# ET6801 register map
Vendor: ETMCU Inc.; File version: v0.0.1
CPU: CM7 r2p1, little endian, MPU, FPU, I-cache, D-cache, ITCM, DTCM, 4 interrupt priority bits
Registers are 32-bit, read-write, reset 0x0 unless marked. A register's access mark holds for its fields unless they carry their own. Offsets are from the block's base; [hi:lo] are bit positions; lines under a group give offsets from that group; {n}, {i} and the like mark numbered series.

## ETIMER — Provide an overview of the purpose and functionality of the peripheral: etim_cfg
Base 0x40024000
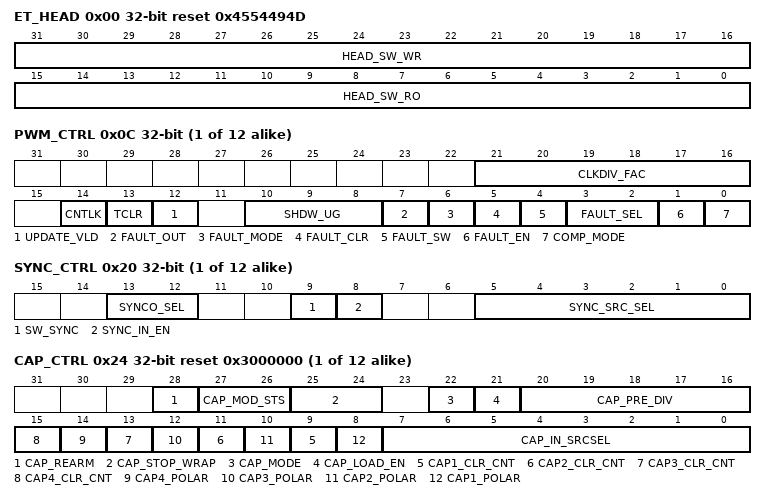
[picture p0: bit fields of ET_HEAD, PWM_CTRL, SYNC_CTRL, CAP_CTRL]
0x00 ET_HEAD reset 0x4554494D
  [31:16] HEAD_SW_WR — 软件测试读写寄存器，硬件无访问
  [15:0] HEAD_SW_RO ro — 软件只读上报寄存器，硬件无访问,ETIM的ASICII 码表示
{0x4+0x30*i} CORE[{i}] (i=0..11) group — CFG_ETIM_CORE
  0x00 COMPA
    [31:0] PWM_COMPA — eTimer COMPA比较值
  0x04 COMPB
    [31:0] PWM_COMPB — eTimer COMPB比较值
  0x08 EVENT_CNT
    [31:0] PWM_EVTCNT — eTimer输出配置值，计数到该寄存器配置值，有个对应的事件输出
  0x0C PWM_CTRL
    [21:16] CLKDIV_FAC — eTimer模块计数分频因子,计数值0~63； 实际分频数比配置值多1
    [14] CNTLK — 软件配置counter锁存，写1清，产生高脉冲
    [13] TCLR — 软件配置timer清零，写1清，产生高脉冲
    [12] UPDATE_VLD — eTimer COMPA/COMPB比较值更新标识，软件写1，硬件清零 该寄存器为1时，表示COMPA、COMPB已经刷新完成，硬件可以在shadow模式下更新配置值，避免shadow模式下只更新成功其中一个值； 与cfg_pwm_shdw_ug使用同一个寄存器，保证可以同时配置，使cfg_pwm_compa[31:0]， cfg_etm_pwm_compb[31:0]可以同时生效；
    [10:8] SHDW_UG — 影子加载模式使能，计数到周期值更新（相应bit为1使能对应影子加载模式；不使能默认为立即加载） bit0：周期值 ； bit1：COMPA+COMPB ； bit2：事件配置寄存器值；
    [7] FAULT_OUT — eTimer fault模式输出电平 0：输出低电平； 1：输出高电平；
    [6] FAULT_MODE — eTimer fault模式 0：CBC模式； 1：one-shot模式；
    [5] FAULT_CLR — eTimer one-shot fault模式清零信号，写1清，产生高脉冲
    [4] FAULT_SW — eTimer fault模式软件输入信号
    [3:2] FAULT_SEL — eTimer fault模式输入选择 0：软件输入； 1：XBAR0输入； 2：XBAR1输入； other：reserved。（硬件默认为软件输入）
    [1] FAULT_EN — eTimer是否进入fault模式 0：不进入fault模式； 1：进入fault模式；
    [0] COMP_MODE — eTimer比较模式 0：COMPA单一比较模式； 1：COMPA+COMPB模式；
  0x10 TIMER_CYC reset 0xFFFFFFFF
    [31:0] PWM_TCYC — 软件配置couter周期值
  0x14 LKCNT_RPT ro
    [31:0] PWM_LKCNT — cfg_etim_pwm_cntlk_r锁存后Counter上报值，只读
  0x18 RLCNT_RPT ro
    [31:0] PWM_RLCNT — Counter实时值上报，只读
  0x1C CTRPHS
    [31:0] SYNC_CTRPHS — 相位控制寄存器,同步信号到来时，加载此寄存器到计数器中
  0x20 SYNC_CTRL
    [13:12] SYNCO_SEL — 内部同步源etim_sync_out信号源选择： 'd0:选择软件配置同步 'd1:选择ETIM计数到周期同步 'd2:关闭etim_sync_out输出信号（输出为0） 'd3: 关闭etim_sync_out输出信号（输出为0）
    [9] SW_SYNC — 软件强制同步（写清） 'b0:无影响 'b1:写1产生软件强制同步
    [8] SYNC_IN_EN — Sync in模式选择 'b0:关闭sync_in进来的信号 'b1:使能sync_in进来的信号
    [5:0] SYNC_SRC_SEL — 同步输入源选择 选择SPWM、INPUTXBAR、ETIM的同步信号，如下所示： 'd0:SPWM0_SYNC 'd1:SPWM1_SYNC 'd2:SPWM2_SYNC 'd3:SPWM3_SYNC 'd4:SPWM4_SYNC 'd5:SPWM5_SYNC 'd6:SPWM6_SYNC 'd7:SPWM7_SYNC 'd8:SPWM8_SYNC 'd9:SPWM9_SYNC 'd10:SPWM10_SYNC 'd11: SPWM11_SYNC d12: SPWM12_SYNC 'd13: SPWM13_SYNC 'd14: SPWM14_SYNC 'd15: SPWM15_SYNC 'd16: SPWM16_SYNC 'd17: SPWM17_SYNC 'd18:INPUTXBAR0(XBAR CAP输入源低6位) 'd19: INPUTXBAR1(XBAR CAP输入源低6位) 'd20: INPUTXBAR2(XBAR CAP输入源低6位) 'd21: INPUTXBAR3(XBAR CAP输入源低6位) 'd22: INPUTXBAR4(XBAR CAP输入源低6位) 'd23: INPUTXBAR5(XBAR CAP输入源低6位) 'd24:ETIM0_SYNC_OUT 'd25:ETIM1_SYNC_OUT 'd26:ETIM2_SYNC_OUT 'd27:ETIM3_SYNC_OUT 'd28:ETIM4_SYNC_OUT 'd29:ETIM5_SYNC_OUT 'd30:ETIM6_SYNC_OUT 'd31:ETIM7_SYNC_OUT 'd32:ETIM8_SYNC_OUT 'd33:ETIM9_SYNC_OUT 'd34:ETIM10_SYNC_OUT 'd35:ETIM11_SYNC_OUT '36-63:1'b0'
  0x24 CAP_CTRL reset 0x3000000
    [28] CAP_REARM — 重新加载 'b0:无作用 'b1:针对one-shot模式 复位MOD4寄存器值到0，解冻MOD4计数器，使能CAP寄存器加载
    [27:26] CAP_MOD_STS ro — d0: CAP1寄存器在下一个捕获时刻加载 'd1: CAP2寄存器在下一个捕获时刻加载 'd2: CAP3寄存器在下一个捕获时刻加载 'd3: CAP4寄存器在下一个捕获时刻加载
    [25:24] CAP_STOP_WRAP — One-shot：停止计数值，停止时cap1~cap4寄存器将会被冻结 Continuous: 从该数开始重新进行计数 'd0:在捕获事件1发生后停止（one-shot）或者在捕获事件1后重新环绕 'd1:在捕获事件2发生后停止（one-shot）或者在捕获事件2后重新环绕 'd2:在捕获事件3发生后停止（one-shot）或者在捕获事件3后重新环绕 'd3:在捕获事件4发生后停止（one-shot）或者在捕获事件4后重新环绕
    [22] CAP_MODE — 捕获模式选择 'b0:continuous模式 'b1:one-shot模式
    [21] CAP_LOAD_EN — 加载CAP1~CAP4寄存器值 'b0:在捕获事件发生时，关闭加载CAP1~CAP4 'b1: 在捕获事件发生时，使能加载CAP1~CAP4
    [20:16] CAP_PRE_DIV — 配置CAP 预分频 'h0:by pass 'h1:预分频2 'h2:预分频4 'h3:预分频6 ...... 'h1e:预分频60 'h1f:预分频62
    [2n+7] CAP{n}_CLR_CNT (n=1..4) — 捕获事件{n}计数器清零 'b0:计数器不清零（绝对时间戳） 'b1:计数器清零（相对时间戳）
    [14] CAP4_POLAR — 捕获事件4极性选择 'b0:上升沿捕获事件4 'b1:下降沿捕获事件4
    [12] CAP3_POLAR — 捕获事件4极性选择 'b0:上升沿捕获事件3 'b1:下降沿捕获事件3
    [10] CAP2_POLAR — 捕获事件2极性选择 'b0:上升沿捕获事件2 'b1:下降沿捕获事件2
    [8] CAP1_POLAR — 捕获事件1极性选择 'b0:上升沿捕获事件1 'b1:下降沿捕获事件1
    [7:0] CAP_IN_SRCSEL — 8'd0 INPUTXBAR1 8'd1 INPUTXBAR2 8'd2 INPUTXBAR3 8'd3 INPUTXBAR4 8'd4 INPUTXBAR5 8'd5 INPUTXBAR6 8'd6 INPUTXBAR7 8'd7 INPUTXBAR8 8'd8 INPUTXBAR9 8'd9 INPUTXBAR10 8'd10 INPUTXBAR11 8'd11 INPUTXBAR12 8'd12 INPUTXBAR13 8'd13 INPUTXBAR14 8'd14 INPUTXBAR15 8'd15 INPUTXBAR16 8'd16 OUTPUTXBAR1 8'd17 OUTPUTXBAR2 8'd18 OUTPUTXBAR3 8'd19 OUTPUTXBAR4 8'd20 OUTPUTXBAR5 8'd21 OUTPUTXBAR6 8'd22 OUTPUTXBAR7 8'd23 OUTPUTXBAR8 8'd24 OUTPUTXBAR9 8'd25 OUTPUTXBAR10 8'd26 OUTPUTXBAR11 8'd27 OUTPUTXBAR12 8'd28 CLU1 8'd29 CLU2 8'd30 CLU3 8'd31 CLU4 8'd32 UART_rx0 8'd33 UART_rx1 8'd34 UART_rx2 8'd35 UART_rx3 8'd36 UART_rx4 8'd37 UART_rx5 8'd38 UART_rx6 8'd39 UART_rx7 8'd40 LIN0_RX 8'd41 LIN1_RX 8'd42 SPWM1 8'd43 SPWM2 8'd44 SPWM3 8'd45 SPWM4 8'd46 SPWM5 8'd47 SPWM6 8'd48 SPWM7 8'd49 SPWM8 8'd50 SPWM9 8'd51 SPWM10 8'd52 SPWM11 8'd53 SPWM12 8'd54 SPWM13 8'd55 SPWM14 8'd56 SPWM15 8'd57 SPWM16 8'd58 SPWM17 8'd59 SPWM18 8'd60 SPWM19 8'd61 SPWM20 8'd62 SPWM21 8'd63 SPWM22 8'd64 SPWM23 8'd65 SPWM24 8'd66 SPWM25 8'd67 SPWM26 8'd68 SPWM27 8'd69 SPWM28 8'd70 SPWM29 8'd71 SPWM30 8'd72 SPWM31 8'd73 SPWM32 8'd74 SPWM33 8'd75 SPWM34 8'd76 SPWM35 8'd77 SPWM36 8'd78 ETIM1_PWM 8'd79 ETIM2_PWM 8'd80 ETIM3_PWM 8'd81 ETIM4_PWM 8'd82 ETIM5_PWM 8'd83 ETIM6_PWM 8'd84 ETIM7_PWM 8'd85 ETIM8_PWM 8'd86 ETIM9_PWM 8'd87 ETIM10_PWM 8'd88 ETIM11_PWM 8'd89 ETIM12_PWM 8'd90 CMPSS1_CTRIPH 8'd91 CMPSS2_CTRIPH 8'd92 CMPSS3_CTRIPH 8'd93 CMPSS4_CTRIPH 8'd94 CMPSS5_CTRIPH 8'd95 CMPSS6_CTRIPH 8'd96 CMPSS7_CTRIPH 8'd97 CMPSS8_CTRIPH 8'd98 CMPSS9_CTRIPH 8'd99 CMPSS10_CTRIPH 8'd100 CMPSS11_CTRIPH 8'd101 CMPSS1_CTRIPL 8'd102 0 CMPSS2_CTRIPL 8'd103 1 CMPSS3_CTRIPL 8'd104 2 CMPSS4_CTRIPL 8'd105 3 CMPSS5_CTRIPL 8'd106 4 CMPSS6_CTRIPL 8'd107 5 CMPSS7_CTRIPL 8'd108 6 CMPSS8_CTRIPL 8'd109 7 CMPSS9_CTRIPL 8'd110 8 CMPSS10_CTRIPL 8'd111 9 CMPSS11_CTRIPL 8'd112 0 CMPSS1_CTRIPH OR CMPSS1_CTRIPL 8'd113 1 CMPSS2_CTRIPH OR CMPSS2_CTRIPL 8'd114 2 CMPSS3_CTRIPH OR CMPSS3_CTRIPL 8'd115 3 CMPSS4_CTRIPH OR CMPSS4_CTRIPL 8'd116 4 CMPSS5_CTRIPH OR CMPSS5_CTRIPL 8'd117 5 CMPSS6_CTRIPH OR CMPSS6_CTRIPL 8'd118 6 CMPSS7_CTRIPH OR CMPSS7_CTRIPL 8'd119 7 CMPSS8_CTRIPH OR CMPSS8_CTRIPL 8'd120 8 CMPSS9_CTRIPH OR CMPSS9_CTRIPL 8'd121 9 CMPSS10_CTRIPH OR CMPSS10_CTRIPL 8'd122 0 CMPSS11_CTRIPH OR CMPSS11_CTRIPL 8'd123 1 ADC1_CEVT1 8'd124 2 ADC1_CEVT2 8'd125 3 ADC1_CEVT3 8'd126 4 ADC1_CEVT4 8'd127 5 ADC2_CEVT1 8'd128 6 ADC2_CEVT2 8'd129 7 ADC2_CEVT3 8'd130 8 ADC2_CEVT4 8'd131 9 ADC3_CEVT1 8'd132 0 ADC3_CEVT2 8'd133 1 ADC3_CEVT3 8'd134 2 ADC3_CEVT4 8'd135 3 SDFM1FL1_CEVT1 8'd136 4 SDFM1FL2_CEVT1 8'd137 5 SDFM1FL3_CEVT1 8'd138 6 SDFM1FL4_CEVT1 8'd139 7 SDFM1FL1_CEVT2 8'd140 8 SDFM1FL2_CEVT2 8'd141 9 SDFM1FL3_CEVT2 8'd142 0 SDFM1FL4_CEVT2 8'd143 1 SDFM1FL1_COMPZ 8'd144 2 SDFM1FL2_COMPZ 8'd145 3 SDFM1FL3_COMPZ 8'd146 4 SDFM1FL4_COMPZ 8'd147 5 SDFM2FL1_CEVT1 8'd148 6 SDFM2FL2_CEVT1 8'd149 7 SDFM2FL3_CEVT1 8'd150 8 SDFM2FL4_CEVT1 8'd151 9 SDFM2FL1_CEVT2 8'd152 0 SDFM2FL2_CEVT2 8'd153 1 SDFM2FL3_CEVT2 8'd154 2 SDFM2FL4_CEVT2 8'd155 3 SDFM2FL1_COMPZ 8'd156 4 SDFM2FL2_COMPZ 8'd157 5 SDFM2FL3_COMPZ 8'd158 6 SDFM2FL4_COMPZ 8'd159 7 SDFM3FL1_CEVT1 8'd160 8 SDFM3FL2_CEVT1 8'd161 9 SDFM3FL3_CEVT1 8'd162 0 SDFM3FL4_CEVT1 8'd163 1 SDFM3FL1_CEVT2 8'd164 2 SDFM3FL2_CEVT2 8'd165 3 SDFM3FL3_CEVT2 8'd166 4 SDFM3FL4_CEVT2 8'd167 5 SDFM3FL1_COMPZ 8'd168 6 SDFM3FL2_COMPZ 8'd169 7 SDFM3FL3_COMPZ 8'd170 8 SDFM3FL4_COMPZ 8'd171 9 SDFM4FL1_CEVT1 8'd172 0 SDFM4FL2_CEVT1 8'd173 1 SDFM4FL3_CEVT1 8'd174 2 SDFM4FL4_CEVT1 8'd175 3 SDFM4FL1_CEVT2 8'd176 4 SDFM4FL2_CEVT2 8'd177 5 SDFM4FL3_CEVT2 8'd178 6 SDFM4FL4_CEVT2 8'd179 7 SDFM4FL1_COMPZ 8'd180 8 SDFM4FL2_COMPZ 8'd181 9 SDFM4FL3_COMPZ 8'd182 0 SDFM4FL4_COMPZ 8'd183 1 SDFM1FL1_CEVT1 OR SDFM1FL1_CEVT2 8'd184 2 SDFM1FL2_CEVT1 OR SDFM1FL2_CEVT2 8'd185 3 SDFM1FL3_CEVT1 OR SDFM1FL3_CEVT2 8'd186 4 SDFM1FL4_CEVT1 OR SDFM1FL4_CEVT2 8'd187 5 SDFM2FL1_CEVT1 OR SDFM2FL1_CEVT2 8'd188 6 SDFM2FL2_CEVT1 OR SDFM2FL2_CEVT2 8'd189 7 SDFM2FL3_CEVT1 OR SDFM2FL3_CEVT2 8'd190 8 SDFM2FL4_CEVT1 OR SDFM2FL4_CEVT2 8'd191 9 SDFM3FL1_CEVT1 OR SDFM3FL1_CEVT2 8'd192 0 SDFM3FL2_CEVT1 OR SDFM3FL2_CEVT2 8'd193 1 SDFM3FL3_CEVT1 OR SDFM3FL3_CEVT2 8'd194 2 SDFM3FL4_CEVT1 OR SDFM3FL4_CEVT2 8'd195 3 SDFM4FL1_CEVT1 OR SDFM4FL1_CEVT2 8'd196 4 SDFM4FL2_CEVT1 OR SDFM4FL2_CEVT2 8'd197 5 SDFM4FL3_CEVT1 OR SDFM4FL3_CEVT2 8'd198 6 SDFM4FL4_CEVT1 OR SDFM4FL4_CEVT2 8'd199 7 CLB1OUT14 8'd200 8 CLB2OUT14 8'd201 9 CLB3OUT14 8'd202 0 CLB4OUT14 8'd203 1 CLB5OUT14 8'd204 2 CLB6OUT14 8'd205 3 CLB1OUT15 8'd206 4 CLB2OUT15 8'd207 5 CLB3OUT15 8'd208 6 CLB4OUT15 8'd209 7 CLB5OUT15 8'd210 8 CLB6OUT15 8'd211 9 GPIO2ETIM_1 8'd212 0 GPIO2ETIM_2 8'd213 1 GPIO2ETIM_3 8'd214 2 GPIO2ETIM_4 8'd215 3 GPIO2ETIM_5 8'd216 4 GPIO2ETIM_6 8'd217 5 GPIO2ETIM_7 8'd218 6 GPIO2ETIM_8
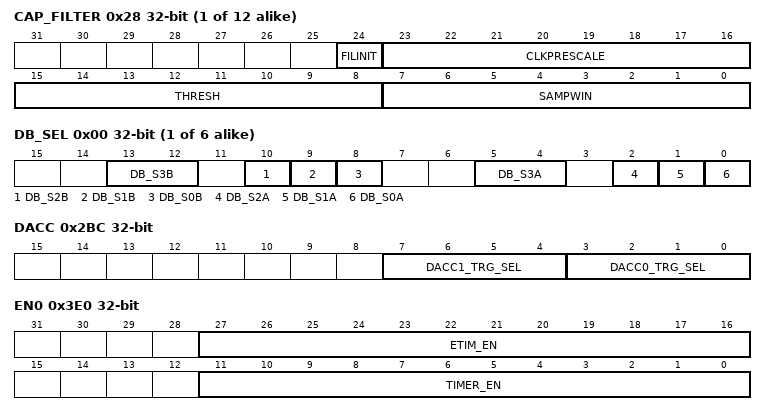
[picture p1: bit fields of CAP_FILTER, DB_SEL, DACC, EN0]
  0x28 CAP_FILTER
    [24] FILINIT — dgt_flt初始化。 'b0:所有样本初始化为0 'b1:将所有样本初始化为滤波器输入值
    [23:16] CLKPRESCALE — 采样时钟预分频值
    [15:8] THRESH — 滤波器统计阈值，当0或者1的个数大于等于该阈值（thresh+1）时，输出对应的值
    [7:0] SAMPWIN — 滤波器样本窗口大小。要监控的采样数为sampwin +1。
  0x2C EVT_TO_ADC
    [2:0] EVT_TO_ADC — d0:计数到周期值事件送给ADC 'd1:计数到0事件送给ADC 'd2:计数到COMPA事件送给ADC 'd3:计数到COMPB事件送给ADC 其他:计数到事件值得事件送给ADC
{0x244+0x14*i} OUT[{i}] (i=0..5) group — CFG_ETIM_OUT
  0x00 DB_SEL
    [13:12] DB_S3B — 死区b支路第3个MUX的输出选择 'd0，'d3：选择不做任何延迟的，旁路输出，即选择DB模块输入的b支路PWM信号作为输出； 'b 01：选择b支路第2个MUX的输出。 'b 10：选择将b支路第2个MUX的输出取反后再输出。
    [10] DB_S2B — 死区b支路第2个MUX的输出选择 'b 0：选择b支路第1个MUX的输出； 'b 1：选择将b支路第1个MUX的输出进行下降沿延迟处理之后作为第2个MUX的输出。
    [9] DB_S1B — 死区b支路第1个MUX的输出选择 'b 0：选择将b支路第0个MUX的输出； 'b 1：选择将b支路第0个MUX的输出进行上升沿延迟处理之后作为第1个MUX的输出
    [8] DB_S0B — 死区b支路第0个MUX的输出选择。 'b 0：选择选择DB模块输入的b支路PWM信号，即srpwmb信号； 'b 1：选择DB模块输入的a支路PWM信号，即srpwma信号。
    [5:4] DB_S3A — 死区a支路第3个MUX选择 'b 00，'b11：选择不做任何延迟的，旁路输出，即选择DB模块输入的b支路PWM信号作为输出； 'b 01：选择b支路第2个MUX的输出。 'b 10：选择将b支路第2个MUX的输出取反后再输出。
    [2] DB_S2A — 死区a支路第2个MUX选择 'b 0：选择a支路第1个MUX的输出； 'b 1：选择将a支路第1个MUX的输出进行下降沿延迟处理之后作为第2个MUX的输出。
    [1] DB_S1A — 死区a支路第1个MUX选择 'b 0：选择将a支路第0个MUX的输出； 'b 1：选择将a支路第0个MUX的输出进行上升沿延迟处理之后作为第1个MUX的输出
    [0] DB_S0A — 死区a支路第0个MUX的输出选择 'b 0：选择DB模块输入的a支路PWM信号，即pwma信号； 'b 1：选择DB模块输入的b支路PWM信号，即pwmb信号。
  0x04 APOS_DLY
    [13:0] DB_APOS_DLY — pwma 上升沿延迟配置。14bit配置值，取值范围0~16383。用于DB模块调整发波信号上升沿。
  0x08 ANEG_DLY
    [13:0] DB_ANEG_DLY — pwma 下降沿延迟配置。14bit配置值，取值范围0~16383，用于DB模块调整发波信号下降沿。
  0x0C BPOS_DLY
    [13:0] DB_BPOS_DLY — pwmb 上升沿延迟配置。14bit配置值，取值范围0~16383。用于DB模块调整发波信号上升沿。
  0x10 BNEG_DLY
    [13:0] DB_BNEG_DLY — pwmb 下降沿延迟配置。14bit配置值，取值范围0~16383，用于DB模块调整发波信号下降沿。
0x2BC DACC
  [7:4] DACC1_TRG_SEL — ETIM送给DACC1触发源选择寄存器： 选择同dacc0_trg_sel。
  [3:0] DACC0_TRG_SEL — ETIM送给DACC0触发源选择寄存器： 'b0：etim2adc_evt0; 'b1：etim2adc_evt1; 'b2：etim2adc_evt2; 'b3：etim2adc_evt3; 'b4：etim2adc_evt4; 'b5：etim2adc_evt5; 'b6：etim2adc_evt6; 'b7：etim2adc_evt7; 'b8：etim2adc_evt8; 'b9：etim2adc_evt9; 'b10：etim2adc_evt10; 'b12：etim2adc_evt12; 'b13：etim2adc_evt13; 'b14~'b15：etim2adc_evt0。
{0x2C0+4i} CMPC[{i}] (i=0..10) group — CFG_ETIM_CMPC
  0x00 DACCTRG_SEL
    [7:0] SEL — GRP0代表CMPC0，依次类推 bit[7:4] ETIM送给CMPC中DACC1触发源选择寄存器： 选择同cmpc0_dacc0trg_sel。 bit[3:0] : ETIM送给CMPC中DACC0触发源选择寄存器： 'b0：etim2adc_evt0; 'b1：etim2adc_evt1; 'b2：etim2adc_evt2; 'b3：etim2adc_evt3; 'b4：etim2adc_evt4; 'b5：etim2adc_evt5; 'b6：etim2adc_evt6; 'b7：etim2adc_evt7; 'b8：etim2adc_evt8; 'b9：etim2adc_evt9; 'b10：etim2adc_evt10; 'b11：etim2adc_evt11; 'b12：etim2adc_evt12; 'b13：etim2adc_evt13; 'b14~'b15：etim2adc_evt0。
{0x2EC+0x10*i} CAP_CNT[{i}] (i=0..11) group — ETIM_CAP_CNT
  0x00 CAP1 ro
    [31:0] CAP1_CNT — CAP1时间戳计数值
  0x04 CAP2 ro
    [31:0] CAP2_CNT — CAP2时间戳计数值
  0x08 CAP3 ro
    [31:0] CAP3_CNT — CAP3时间戳计数值
  0x0C CAP4 ro
    [31:0] CAP4_CNT — CAP4时间戳计数值
{0x3AC+4i} CMN[{i}] (i=0..11) group — CFG_ETIM_CMN
  0x00 DMA
    [2:0] DMA_CH_SEL — eTimer DMA0通道选择 分别对应etimer 12~etimer0的CEVT4,CEVT3,CEVT2,CEVT1事件 （多余的位为0） 'd3:etimer 1事件 'd2:etimer 1 CNT == CMP事件 'd1:etimer 1 CNT == PRD事件 'd0:etimer 1 CNT_PRD OR CNT_CMP事件
0x3DC SYNC_OUT
  [4:0] SYNC_OUT_SEL — ETIM同步事件输出信号源选择，事件输出到XBAR和IO： 'd0：SPWM1_SYNC_OUT 'd1：SPWM2_SYNC_OUT 'd2：SPWM3_SYNC_OUT 'd3：SPWM4_SYNC_OUT 'd4：SPWM5_SYNC_OUT 'd5：SPWM6_SYNC_OUT 'd6：SPWM7_SYNC_OUT 'd7：SPWM8_SYNC_OUT 'd8：SPWM9_SYNC_OUT 'd9：SPWM10_SYNC_OUT 'd10：SPWM11_SYNC_OUT 'd11：SPWM12_SYNC_OUT 'd12：ETIM1_SYNC_OUT 'd13：ETIM2_SYNC_OUT 'd14：ETIM3_SYNC_OUT 'd15：ETIM4_SYNC_OUT 'd16：ETIM5_SYNC_OUT 'd17：ETIM6_SYNC_OUT 'd18：ETIM7_SYNC_OUT 'd19：ETIM8_SYNC_OUT 'd20：ETIM9_SYNC_OUT 'd21：ETIM10_SYNC_OUT 'd22：ETIM11_SYNC_OUT 'd23：ETIM12_SYNC_OUT 'd24：ETIM13_SYNC_OUT 'd25：ETIM14_SYNC_OUT others:reserved，无输出，输出为0（低电平）
0x3E0 EN0
  [27:16] ETIM_EN — 12个ETIM模块使能信号（相应bit控制对应EITM使能，最后配置） 'b0：ETIM模块不使能； 'b1：ETIM模块使能；
  [11:0] TIMER_EN — 12个ETIM模块计数功能使能；（相应bit控制对应使能） 'b0： 计数功能不使能； 'b1： 计数功能使能； 14个通道同时配置；
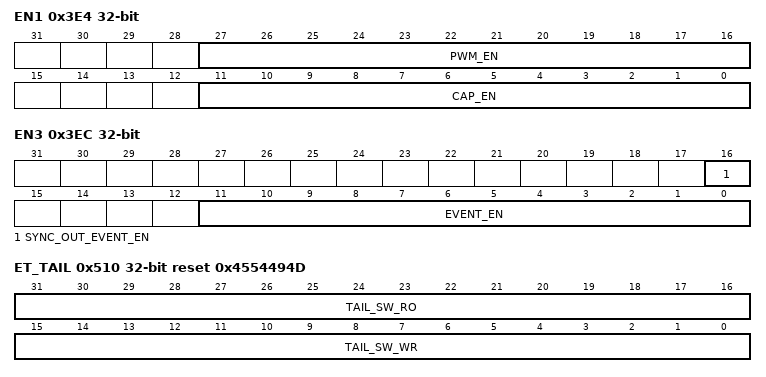
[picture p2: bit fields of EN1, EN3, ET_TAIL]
0x3E4 EN1
  [27:16] PWM_EN — 12个ETIM模块PWM功能使能 （相应bit控制对应使能） 'b0：PWM功能不使能；固定输出为0； 'b1：PWM功能使能； 12个通道同时配置；
  [11:0] CAP_EN — 12个ETIM模块CAP功能使能 （相应bit控制对应使能） 'b0：CAP功能不使能； 'b1：CAP功能使能； 12个通道同时配置；
0x3E8 EN2
  [11:0] CAP_FILTER_EN — 12个ETIM模块CAP滤波功能使能信号 （相应bit控制对应使能） 'b0：CAP滤波功能不使能； 'b1：CAP滤波功能使能； 12个通道同时配置；
0x3EC EN3
  [16] SYNC_OUT_EVENT_EN — 12个ETIM模块event事件输出脉冲扩展使能信号： 'b0：event事件输出不扩展； 'b1：event事件输出扩展；
  [11:0] EVENT_EN — 12个ETIM模块event事件输出功能使能信号 （相应bit控制对应使能） 'b0：event事件输出功能不使能； 'b1：event事件输出功能使能； 12个通道同时配置；
{0x3F0+0x18*i} CMN_INT[{i}] (i=0..11) group — CFG_ETIM_CMN_INT
  0x00 INT_EN
    [11:0] INT_EN — bit0: PWM Fault 时，one -shot模式下中断使能 bit1: PWM Fault 时，CBC模式下中断使能 bit2: Fault模式下溢出中断使能 bit3:配置错误COMPA大于等COMPB中断使能 bit4:计数到COMPA时产生中断使能 bit5:计数到COMPB时产生中断使能 bit6:计数到周期时产生中断使能 bit7:计数器溢出时产生中断使能 bit8: 捕获模式下CEVT1中断使能 bit9: 捕获模式下CEVT2中断使能 bit10: 捕获模式下CEVT3中断使能 bit11: 捕获模式下CEVT4中断使能
  0x04 INT_MASK reset 0x8
    [11:0] INT_MASK — bit0: PWM Fault 时，one -shot模式下中断屏蔽 bit1: PWM Fault 时，CBC模式下中断屏蔽 bit2: Fault模式下溢出中断屏蔽 bit3:配置错误COMPA大于等COMPB中断屏蔽(默认屏蔽) bit4:计数到COMPA时产生中断屏蔽 bit5:计数到COMPB时产生中断屏蔽 bit6:计数到周期时产生中断屏蔽 bit7:计数器溢出时产生中断屏蔽 bit8: 捕获模式下CEVT1中断屏蔽 bit9: 捕获模式下CEVT2中断屏蔽 bit10: 捕获模式下CEVT3中断屏蔽 bit11: 捕获模式下CEVT4中断屏蔽
  0x08 INT_FORCE_IND
    [11:0] INT_FORCE_IND — bit0: PWM Fault 时，one -shot模式下中断强制测试 bit1: PWM Fault 时，CBC模式下中断强制测试 bit2: Fault模式下溢出中断强制测试 bit3:配置错误COMPA大于等COMPB中断强制测试 bit4:计数到COMPA时产生中断强制测试 bit5:计数到COMPB时产生中断强制测试 bit6:计数到周期时产生中断强制测试 bit7:计数器溢出时产生中断强制测试 bit8: 捕获模式下CEVT1中断强制测试 bit9: 捕获模式下CEVT2中断强制测试 bit10: 捕获模式下CEVT3中断强制测试 bit11: 捕获模式下CEVT4中断强制测试
  0x0C INT_CLR
    [11:0] INT_CLR — bit0: PWM Fault 时，one -shot模式下中断清除 bit1: PWM Fault 时，CBC模式下中断清除 bit2: Fault模式下溢出中断清除 bit3:配置错误COMPA大于等COMPB中断清除 bit4:计数到COMPA时产生中断清除 bit5:计数到COMPB时产生中断清除 bit6:计数到周期时产生中断清除 bit7:计数器溢出时产生中断清除 bit8: 捕获模式下CEVT1中断清除 bit9: 捕获模式下CEVT2中断清除 bit10: 捕获模式下CEVT3中断清除 bit11: 捕获模式下CEVT4中断清除
  0x10 INT_RAW_RPT ro
    [11:0] INT_RAW_RPT — bit0: PWM Fault 时，one -shot模式下中断上报信号（屏蔽前） bit1: PWM Fault 时，CBC模式下中断上报信号（屏蔽前） bit2: Fault模式下溢出中断上报信号（屏蔽前） bit3:配置错误COMPA大于等COMPB中断上报信号（屏蔽前） bit4:计数到COMPA时产生中断上报信号（屏蔽前） bit5:计数到COMPB时产生中断上报信号（屏蔽前） bit6:计数到周期时产生中断上报信号（屏蔽前） bit7:计数器溢出时产生中断上报信号（屏蔽前） bit8: 捕获模式下CEVT1中断上报信号（屏蔽前） bit9: 捕获模式下CEVT2中断上报信号（屏蔽前） bit10: 捕获模式下CEVT3中断上报信号（屏蔽前） bit11: 捕获模式下CEVT4中断上报信号（屏蔽前）
  0x14 INT_STATUS_RPT ro
    [11:0] INT_STATUS_RPT — bit0: PWM Fault 时，one -shot模式下中断上报信号（屏蔽后） bit1: PWM Fault 时，CBC模式下中断上报信号（屏蔽后） bit2: Fault模式下溢出中断上报信号（屏蔽后） bit3:配置错误COMPA大于等COMPB中断上报信号（屏蔽后） bit4:计数到COMPA时产生中断上报信号（屏蔽后） bit5:计数到COMPB时产生中断上报信号（屏蔽后） bit6:计数到周期时产生中断上报信号（屏蔽后） bit7:计数器溢出时产生中断上报信号（屏蔽后） bit8: 捕获模式下CEVT1中断上报信号（屏蔽后） bit9: 捕获模式下CEVT2中断上报信号（屏蔽后） bit10: 捕获模式下CEVT3中断上报信号（屏蔽后） bit11: 捕获模式下CEVT4中断上报信号（屏蔽后）
0x510 ET_TAIL reset 0x4554494D
  [31:16] TAIL_SW_RO ro — 软件测试读写寄存器，硬件无访问
  [15:0] TAIL_SW_WR — 软件只读上报寄存器，硬件无访问,ETIM的ASICII 码表示
